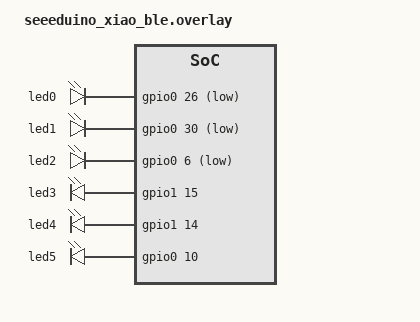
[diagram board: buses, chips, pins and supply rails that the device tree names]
/ {
    aliases {
        led-red = &led0;
        led-green = &led1;
        led-blue = &led2;
        led-red-pcb = &led3;
        led-green-pcb = &led4;
        led-blue-pcb = &led5;
    };

    leds {
        compatible = "gpio-leds";
        status = "okay";
        led0: led_0 {
            gpios = <&gpio0 26 GPIO_ACTIVE_LOW>;
        };
        led1: led_1 {
            gpios = <&gpio0 30 GPIO_ACTIVE_LOW>;
        };
        led2: led_2 {
            gpios = <&gpio0 6 GPIO_ACTIVE_LOW>;
        };
        led3: led_3 {
            gpios = <&gpio1 15 GPIO_ACTIVE_HIGH>;
        };
        led4: led_4 {
            gpios = <&gpio1 14 GPIO_ACTIVE_HIGH>;
        };
        led5: led_5 {
            gpios = <&gpio0 10 GPIO_ACTIVE_HIGH>;
        };
    };
};
&xiao_i2c {
    status = "disabled";
};
&xiao_serial {
    status = "disabled";
};
